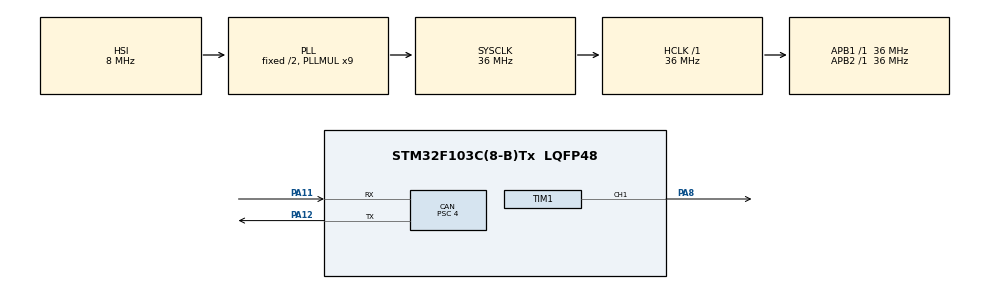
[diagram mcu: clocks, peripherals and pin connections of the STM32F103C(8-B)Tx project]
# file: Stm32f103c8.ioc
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CAN.BS1=CAN_BS1_15TQ
CAN.BS2=CAN_BS2_2TQ
CAN.CalculateBaudRate=500000
CAN.CalculateTimeBit=1999.99
CAN.CalculateTimeQuantum=111.11111111111111
CAN.Mode=CAN_MODE_NORMAL
CAN.Prescaler=4
Mcu.Family=STM32F1
Mcu.Name=STM32F103C(8-B)Tx
Mcu.Package=LQFP48
NVIC.CAN1_RX1_IRQn=true\:0\:0\:false\:false\:true\:true\:true
NVIC.PriorityGroup=NVIC_PRIORITYGROUP_4
NVIC.USB_LP_CAN1_RX0_IRQn=true\:0\:0\:false\:false\:true\:true\:true
PA11.Mode=CAN_Activate
PA11.Signal=CAN_RX
PA12.Mode=CAN_Activate
PA12.Signal=CAN_TX
PA8.Signal=S_TIM1_CH1
ProjectManager.HeapSize=0x200
ProjectManager.StackSize=0x400
ProjectManager.TargetToolchain=MDK-ARM V5
RCC.ADCPresc=RCC_ADCPCLK2_DIV4
RCC.AHBFreq_Value=36000000
RCC.APB1Freq_Value=36000000
RCC.APB1TimFreq_Value=36000000
RCC.APB2Freq_Value=36000000
RCC.APB2TimFreq_Value=36000000
RCC.HCLKFreq_Value=36000000
RCC.PLLMUL=RCC_PLL_MUL9
RCC.SYSCLKFreq_VALUE=36000000
RCC.SYSCLKSource=RCC_SYSCLKSOURCE_PLLCLK
RCC.USBFreq_Value=36000000
SH.S_TIM1_CH1.0=TIM1_CH1,PWM Generation1 CH1
TIM1.Channel-PWM\ Generation1\ CH1=TIM_CHANNEL_1
TIM1.OC1Preload_PWM=ENABLE
TIM1.Period=249
TIM1.Prescaler=6
TIM1.Pulse-PWM\ Generation1\ CH1=199
VP_SYS_VS_ND.Mode=No_Debug
VP_TIM1_VS_ClockSourceINT.Mode=Internal
board=custom

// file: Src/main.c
/* USER CODE BEGIN Header */
/**
  ******************************************************************************
  * @file           : main.c
  * @brief          : Main program body
  ******************************************************************************
  * @attention
  *
  * <h2><center>&copy; Copyright (c) 2020 STMicroelectronics.
  * All rights reserved.</center></h2>
  *
  * This software component is licensed by ST under BSD 3-Clause license,
  * the "License"; You may not use this file except in compliance with the
  * License. You may obtain a copy of the License at:
  *                        opensource.org/licenses/BSD-3-Clause
  *
  ******************************************************************************
  */
/* USER CODE END Header */

#include "main.h"

/* USER CODE BEGIN PM */
#define ADC_RESOLUTION			12

#define MAX_ADC_READ				4095

#define	MAX_PWM_PULS_VALUE	250

/* USER CODE END PM */

CAN_HandleTypeDef hcan;

TIM_HandleTypeDef htim1;

void SystemClock_Config(void);
static void MX_GPIO_Init(void);
static void MX_CAN_Init(void);
static void MX_TIM1_Init(void);
/* USER CODE BEGIN PFP */

static void CAN_TX(void);
static void CAN_RX(void);
static void CAN_Filter_Init(void);

/* USER CODE END PFP */

/* USER CODE BEGIN 0 */

static CAN_TxHeaderTypeDef msg1 ;
static uint32_t mailbox;

static CAN_FilterTypeDef filter;
static CAN_RxHeaderTypeDef Rmsg;
static uint8_t ReceivedMessage[5] ;

/* USER CODE END 0 */

int main(void)
{

  /* MCU Configuration--------------------------------------------------------*/

  /* Reset of all peripherals, Initializes the Flash interface and the Systick. */
 // HAL_Init();

  /* Configure the system clock */
  SystemClock_Config();

  /* Initialize all configured peripherals */
  MX_GPIO_Init();
  MX_CAN_Init();
  MX_TIM1_Init();
  /* USER CODE BEGIN 2 */

	CAN_Filter_Init();
	HAL_CAN_ActivateNotification(&hcan , CAN_IT_RX_FIFO0_MSG_PENDING | CAN_IT_RX_FIFO1_MSG_PENDING);/*Enable CAN Rx interrupt*/
	HAL_CAN_Start(&hcan);/*Start CAN */
	HAL_TIM_PWM_Start(&htim1 , TIM_CHANNEL_1);/*Start PWM Generatoin*/

  /* USER CODE END 2 */

  /* Infinite loop */
  while (1)
  {
		CAN_TX();
  }
}

void SystemClock_Config(void)
{
  RCC_OscInitTypeDef RCC_OscInitStruct = {0};
  RCC_ClkInitTypeDef RCC_ClkInitStruct = {0};

  /** Initializes the CPU, AHB and APB busses clocks
  */
  RCC_OscInitStruct.OscillatorType = RCC_OSCILLATORTYPE_HSI;
  RCC_OscInitStruct.HSIState = RCC_HSI_ON;
  RCC_OscInitStruct.HSICalibrationValue = RCC_HSICALIBRATION_DEFAULT;
  RCC_OscInitStruct.PLL.PLLState = RCC_PLL_ON;
  RCC_OscInitStruct.PLL.PLLSource = RCC_PLLSOURCE_HSI_DIV2;
  RCC_OscInitStruct.PLL.PLLMUL = RCC_PLL_MUL9;
  if (HAL_RCC_OscConfig(&RCC_OscInitStruct) != HAL_OK)
  {
    Error_Handler();
  }
  /** Initializes the CPU, AHB and APB busses clocks
  */
  RCC_ClkInitStruct.ClockType = RCC_CLOCKTYPE_HCLK|RCC_CLOCKTYPE_SYSCLK
                              |RCC_CLOCKTYPE_PCLK1|RCC_CLOCKTYPE_PCLK2;
  RCC_ClkInitStruct.SYSCLKSource = RCC_SYSCLKSOURCE_PLLCLK;
  RCC_ClkInitStruct.AHBCLKDivider = RCC_SYSCLK_DIV1;
  RCC_ClkInitStruct.APB1CLKDivider = RCC_HCLK_DIV1;
  RCC_ClkInitStruct.APB2CLKDivider = RCC_HCLK_DIV1;

  if (HAL_RCC_ClockConfig(&RCC_ClkInitStruct, FLASH_LATENCY_1) != HAL_OK)
  {
    Error_Handler();
  }
}

static void MX_CAN_Init(void)
{

  hcan.Instance = CAN1;
  hcan.Init.Prescaler = 4;
  hcan.Init.Mode = CAN_MODE_NORMAL;
  hcan.Init.SyncJumpWidth = CAN_SJW_1TQ;
  hcan.Init.TimeSeg1 = CAN_BS1_15TQ;
  hcan.Init.TimeSeg2 = CAN_BS2_2TQ;
  hcan.Init.TimeTriggeredMode = DISABLE;
  hcan.Init.AutoBusOff = DISABLE;
  hcan.Init.AutoWakeUp = DISABLE;
  hcan.Init.AutoRetransmission = DISABLE;
  hcan.Init.ReceiveFifoLocked = DISABLE;
  hcan.Init.TransmitFifoPriority = DISABLE;
  if (HAL_CAN_Init(&hcan) != HAL_OK)
  {
    Error_Handler();
  }

}

static void MX_TIM1_Init(void)
{

  TIM_ClockConfigTypeDef sClockSourceConfig = {0};
  TIM_MasterConfigTypeDef sMasterConfig = {0};
  TIM_OC_InitTypeDef sConfigOC = {0};
  TIM_BreakDeadTimeConfigTypeDef sBreakDeadTimeConfig = {0};

  htim1.Instance = TIM1;
  htim1.Init.Prescaler = 6;
  htim1.Init.CounterMode = TIM_COUNTERMODE_UP;
  htim1.Init.Period = 249;
  htim1.Init.ClockDivision = TIM_CLOCKDIVISION_DIV1;
  htim1.Init.RepetitionCounter = 0;
  htim1.Init.AutoReloadPreload = TIM_AUTORELOAD_PRELOAD_DISABLE;
  if (HAL_TIM_Base_Init(&htim1) != HAL_OK)
  {
    Error_Handler();
  }
  sClockSourceConfig.ClockSource = TIM_CLOCKSOURCE_INTERNAL;
  if (HAL_TIM_ConfigClockSource(&htim1, &sClockSourceConfig) != HAL_OK)
  {
    Error_Handler();
  }
  if (HAL_TIM_PWM_Init(&htim1) != HAL_OK)
  {
    Error_Handler();
  }
  sMasterConfig.MasterOutputTrigger = TIM_TRGO_RESET;
  sMasterConfig.MasterSlaveMode = TIM_MASTERSLAVEMODE_DISABLE;
  if (HAL_TIMEx_MasterConfigSynchronization(&htim1, &sMasterConfig) != HAL_OK)
  {
    Error_Handler();
  }
  sConfigOC.OCMode = TIM_OCMODE_PWM1;
  sConfigOC.Pulse = 199;
  sConfigOC.OCPolarity = TIM_OCPOLARITY_HIGH;
  sConfigOC.OCNPolarity = TIM_OCNPOLARITY_HIGH;
  sConfigOC.OCFastMode = TIM_OCFAST_DISABLE;
  sConfigOC.OCIdleState = TIM_OCIDLESTATE_RESET;
  sConfigOC.OCNIdleState = TIM_OCNIDLESTATE_RESET;
  if (HAL_TIM_PWM_ConfigChannel(&htim1, &sConfigOC, TIM_CHANNEL_1) != HAL_OK)
  {
    Error_Handler();
  }
  sBreakDeadTimeConfig.OffStateRunMode = TIM_OSSR_DISABLE;
  sBreakDeadTimeConfig.OffStateIDLEMode = TIM_OSSI_DISABLE;
  sBreakDeadTimeConfig.LockLevel = TIM_LOCKLEVEL_OFF;
  sBreakDeadTimeConfig.DeadTime = 0;
  sBreakDeadTimeConfig.BreakState = TIM_BREAK_DISABLE;
  sBreakDeadTimeConfig.BreakPolarity = TIM_BREAKPOLARITY_HIGH;
  sBreakDeadTimeConfig.AutomaticOutput = TIM_AUTOMATICOUTPUT_DISABLE;
  if (HAL_TIMEx_ConfigBreakDeadTime(&htim1, &sBreakDeadTimeConfig) != HAL_OK)
  {
    Error_Handler();
  }
  HAL_TIM_MspPostInit(&htim1);

}

static void MX_GPIO_Init(void)
{

  /* GPIO Ports Clock Enable */
  __HAL_RCC_GPIOA_CLK_ENABLE();

}

/* USER CODE BEGIN 4 */
void CAN_TX(void)
{
	uint8_t message[1] ={((MAX_PWM_PULS_VALUE * 500) / MAX_ADC_READ)};
	msg1.StdId = 0x64A;
	msg1.IDE = CAN_ID_STD;
	msg1.ExtId = 0 ;
	msg1.DLC = 1 ;
	msg1.RTR = CAN_RTR_DATA;
	msg1.TransmitGlobalTime = DISABLE;

	HAL_CAN_AddTxMessage(&hcan , &msg1 , message , &mailbox);

	while(HAL_CAN_IsTxMessagePending(&hcan , mailbox));

}

void CAN_Filter_Init(void)
{

	/*
		Init Can Filter Bank to Accept all messages
	*/
	filter.FilterIdHigh = 0x000;
	filter.FilterIdLow  = 0x000;
	filter.FilterMaskIdHigh = 0x000;
	filter.FilterMaskIdLow  = 0x000;
	filter.FilterActivation = CAN_FILTER_ENABLE;
	filter.FilterBank = 0;
	filter.FilterFIFOAssignment = CAN_FILTER_FIFO0;
	filter.FilterMode = CAN_FILTERMODE_IDMASK;
  filter.FilterScale =	CAN_FILTERSCALE_32BIT;
	filter.SlaveStartFilterBank = 0;

	HAL_CAN_ConfigFilter(&hcan , &filter);

}

void CAN_RX(void)
{

	/*Wait until There Receiving a message into FIFO*/
	while(! HAL_CAN_GetRxFifoFillLevel(&hcan , CAN_RX_FIFO0));

	/*Get the message and Store the payload Into ReceivedMessage*/
	HAL_CAN_GetRxMessage(&hcan , CAN_RX_FIFO0 , &Rmsg , ReceivedMessage);

}

void HAL_CAN_RxFifo0MsgPendingCallback(CAN_HandleTypeDef *hcan)
{
	/*Get the message and Store the payload Into ReceivedMessage*/
 	HAL_CAN_GetRxMessage(hcan , CAN_RX_FIFO0 , &Rmsg , ReceivedMessage);

	/*Change the PWM according to the received CAN message*/
	htim1.Instance->CCR1 = 	 ReceivedMessage[0];/*The received message must be a value between 0 --> 250*/

}
/* USER CODE END 4 */

void Error_Handler(void)
{
}

/************************ (C) COPYRIGHT STMicroelectronics *****END OF FILE****/
